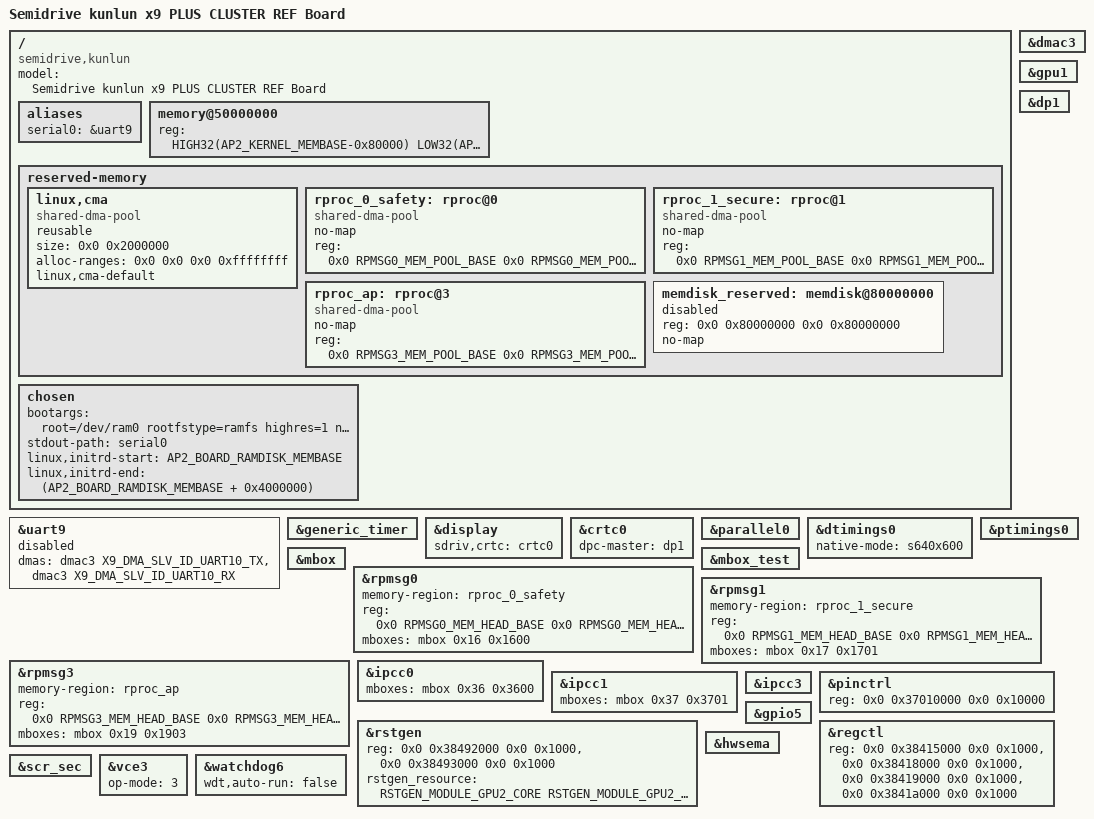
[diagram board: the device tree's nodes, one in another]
/*
 * Semidrive kunlun platform DTS file
 *
 * Copyright (C) 2019, Semidrive  Communications Inc.
 *
 * This file is licensed under a dual GPLv2 or X11 license.
 */

/dts-v1/;

#include "../x9_high-plus_cluster.dtsi"
#include "../x9_high-plus_ref_cluster-clk-ctrl.dtsi"
#include "../lcd-timings.dtsi"
#include <dt-bindings/pinctrl/pins-sdx9.h>
#include <dt-bindings/memmap/x9_high-plus/projects/default/image_cfg.h>
#include <dt-bindings/rpmsg/sd,x9hp-ap2.h>

/ {
	model = "Semidrive kunlun x9 PLUS CLUSTER REF Board";

	compatible = "semidrive,kunlun";

	aliases {
		serial0 = &uart9;
	};

	memory@50000000 {
		device_type = "memory";
		reg = <HIGH32(AP2_KERNEL_MEMBASE-0x80000) LOW32(AP2_KERNEL_MEMBASE-0x80000) HIGH32(AP2_KERNEL_MEMSIZE) LOW32(AP2_KERNEL_MEMSIZE) >;/*512MB */
	};

	reserved-memory {
		#address-cells = <2>;
		#size-cells = <2>;
		ranges;

		/* Default Common CMA Pool */
		/* QUIRK: Must be kept in the lower 4096 MiBs of DRAM banks for VE */
		linux,cma {
			compatible = "shared-dma-pool";
			reusable;
			size = <0x0 0x2000000>; /* 32MB */
			/* 4GB maximum in case of 32-bit only capable devices */
			alloc-ranges = <0x0 0x0 0x0 0xffffffff>;
			linux,cma-default;
		};

		rproc_0_safety: rproc@0 {
			compatible = "shared-dma-pool";
			no-map;
			reg = <0x0 RPMSG0_MEM_POOL_BASE 0x0 RPMSG0_MEM_POOL_SIZE>;
		};

		rproc_1_secure: rproc@1 {
			compatible = "shared-dma-pool";
			no-map;
			reg = <0x0 RPMSG1_MEM_POOL_BASE 0x0 RPMSG1_MEM_POOL_SIZE>;
		};

		rproc_ap: rproc@3 {
			compatible = "shared-dma-pool";
			no-map;
			reg = <0x0 RPMSG3_MEM_POOL_BASE 0x0 RPMSG3_MEM_POOL_SIZE>;
		};

		memdisk_reserved: memdisk@80000000 {
			reg = <0x0 0x80000000 0x0 0x80000000>;
			no-map;
			status = "disabled";
		};
	};

	chosen {
		bootargs = "root=/dev/ram0 rootfstype=ramfs highres=1 nr_cpus=1 loglevel=4 console=ttyS0,115200n8 fbcon=map:1 androidboot.mode=normal androidboot.selinux=permissive androidboot.debuggable=0 androidboot.dm_verity=disable init=/init";
		stdout-path = "serial0";
		linux,initrd-start = <AP2_BOARD_RAMDISK_MEMBASE>;
		linux,initrd-end   = <(AP2_BOARD_RAMDISK_MEMBASE + 0x4000000)>;/* 64MB */
	};

};

&dmac3 {
	status = "okay";
};

&uart9 {
	dmas = <&dmac3 X9_DMA_SLV_ID_UART10_TX>, <&dmac3 X9_DMA_SLV_ID_UART10_RX>;
	dma-names = "tx", "rx";
	status = "disabled";
};

&generic_timer {
	status = "okay";
};

&display {
	sdriv,crtc = <&crtc0>;
	status = "okay";
};

&gpu1 {
	status = "okay";
};

&dp1 {
	status = "okay";
};

&crtc0 {
	dpc-master = <&dp1>;
	status = "okay";
};

&parallel0 {
	status = "okay";
};

&dtimings0 {
	native-mode = <&s640x600>;
};

&ptimings0 {
	status = "okay";
};

&mbox {
	status = "okay";
};

&mbox_test {
	status = "okay";
};

&rpmsg0 {
	memory-region = <&rproc_0_safety>;
	reg = <0x0 RPMSG0_MEM_HEAD_BASE 0x0 RPMSG0_MEM_HEAD_SIZE>;
	mboxes = <&mbox 0x16 0x1600>;
	status = "okay";
};

&rpmsg1 {
	memory-region = <&rproc_1_secure>;
	reg = <0x0 RPMSG1_MEM_HEAD_BASE 0x0 RPMSG1_MEM_HEAD_SIZE>;
	mboxes = <&mbox 0x17 0x1701>;
	status = "okay";
};

&rpmsg3 {
	memory-region = <&rproc_ap>;
	reg = <0x0 RPMSG3_MEM_HEAD_BASE 0x0 RPMSG3_MEM_HEAD_SIZE>;
	mboxes = <&mbox 0x19 0x1903>;
	status = "okay";
};

&ipcc0 {
	mboxes = <&mbox 0x36 0x3600>;
	status = "okay";
};

&ipcc1 {
	mboxes = <&mbox 0x37 0x3701>;
	status = "okay";
};

&ipcc3 {
	status = "okay";
};

&pinctrl {
	reg = <0x0 0x37010000 0x0 0x10000>;
};

&gpio5 {
	status = "okay";
};

&rstgen {
	reg = <0x0 0x38492000 0x0 0x1000>,	/* gpu2 core */
		<0x0 0x38493000 0x0 0x1000>;	/* gpu2 ss */

	rstgen_resource = <
		RSTGEN_MODULE_GPU2_CORE
		RSTGEN_MODULE_GPU2_SS

	>;
	status = "okay";
};

&regctl {
	reg = <0x0 0x38415000 0x0 0x1000>,
		<0x0 0x38418000 0x0 0x1000>,
		<0x0 0x38419000 0x0 0x1000>,
		<0x0 0x3841a000 0x0 0x1000>;
	reg-names = "SDRV_REG_REMAP",
			"SDRV_REG_BOOTREASON",
			"SDRV_REG_HWID",
			"SDRV_REG_STATUS";
	status = "okay";
};

&hwsema {
        status = "okay";
};

&scr_sec {
        status = "okay";
};

&vce3 {
   /*
 	* op-mode options:
 	* bit 0: rng enable(1) or disable(0)
 	* bit 1: ce enable(1) or disable(0)
 	*/
 	op-mode = <3>;
	status = "okay";
};

&watchdog6 {
	wdt,auto-run = "false";
	status = "okay";
};
